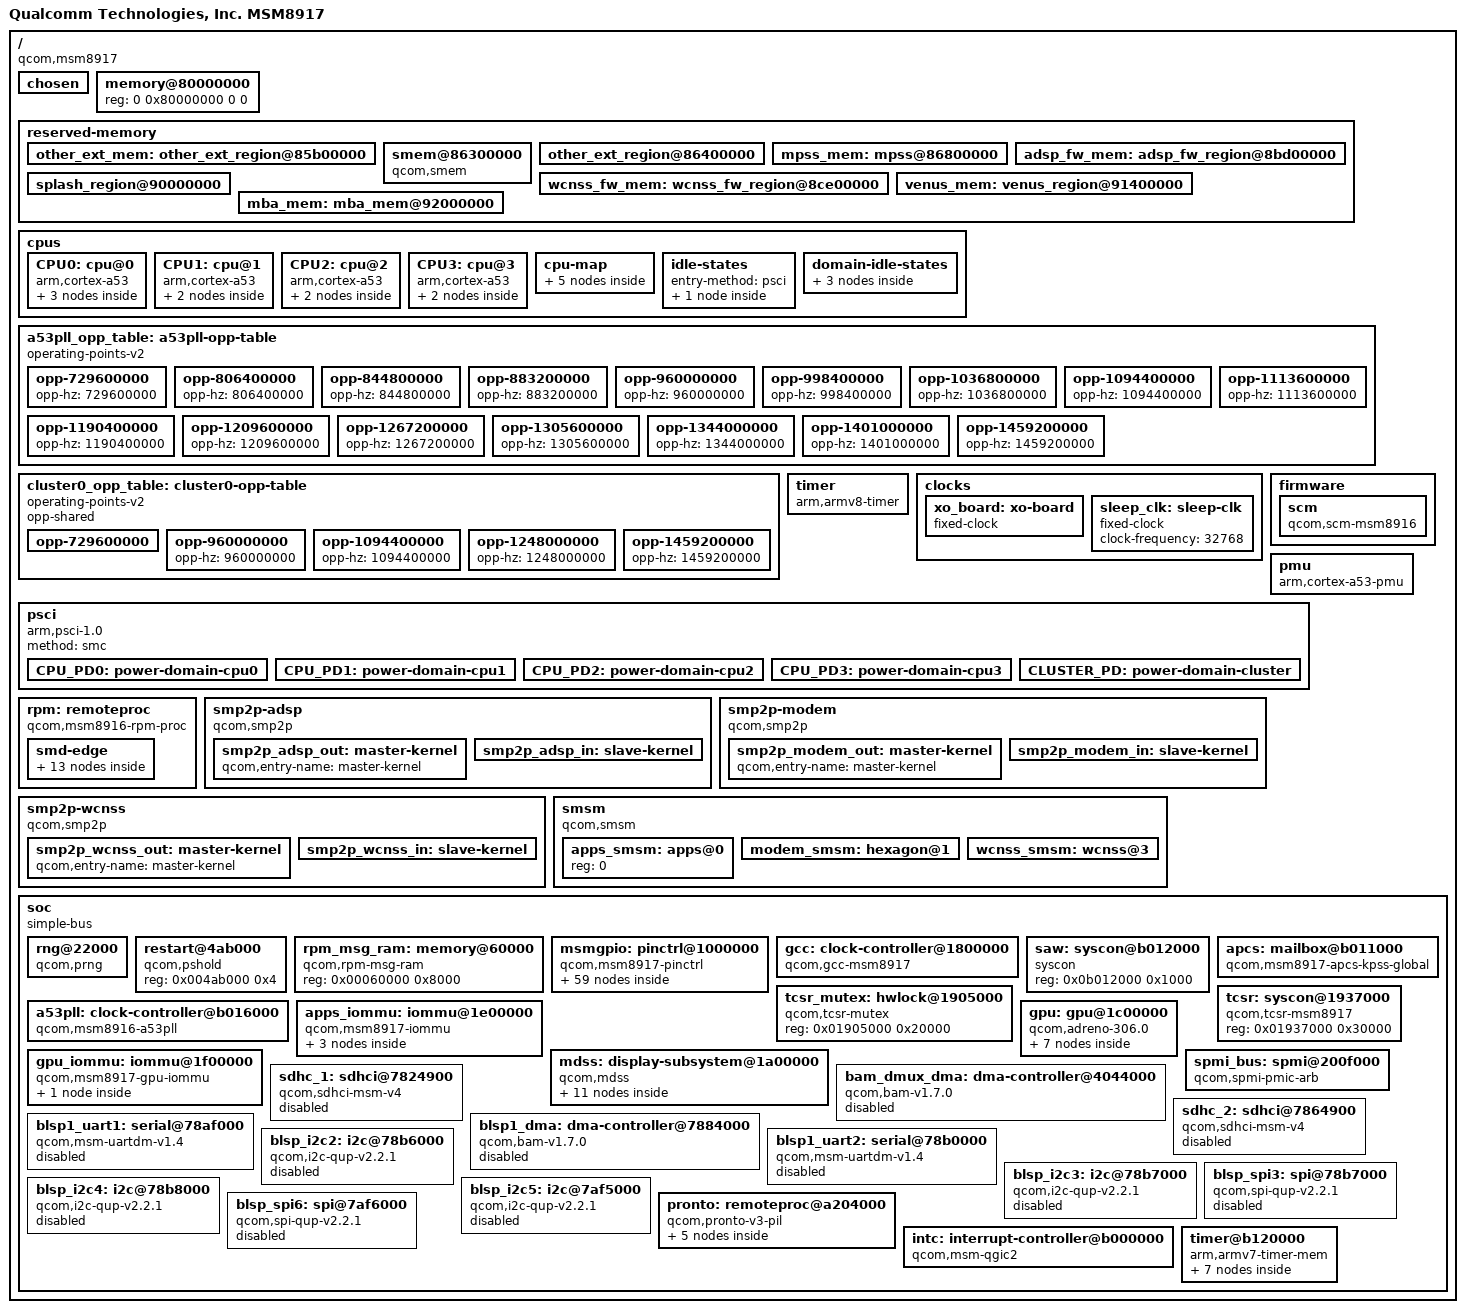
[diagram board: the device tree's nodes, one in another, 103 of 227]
// SPDX-License-Identifier: GPL-2.0-only

#include <dt-bindings/clock/qcom,gcc-msm8917.h>
#include <dt-bindings/clock/qcom,rpmcc.h>
#include <dt-bindings/interrupt-controller/arm-gic.h>
#include <dt-bindings/power/qcom-rpmpd.h>

/ {
	model = "Qualcomm Technologies, Inc. MSM8917";
	compatible = "qcom,msm8917";
	qcom,msm-id = <303 0x0>, <308 0x0>, <309 0x0>;
	interrupt-parent = <&intc>;

	#address-cells = <2>;
	#size-cells = <2>;

	chosen { };

	memory@80000000 {
		device_type = "memory";
		/* We expect the bootloader to fill in the reg */
		reg = <0 0x80000000 0 0>;
	};

	reserved-memory {
		#address-cells = <2>;
		#size-cells = <2>;
		ranges;

		other_ext_mem: other_ext_region@85b00000 {
			reg = <0x0 0x85b00000 0x0 0xd00000>;
			no-map;
		};

		smem@86300000 {
			compatible = "qcom,smem";
			reg = <0x0 0x86300000 0x0 0x100000>;
			no-map;

			hwlocks = <&tcsr_mutex 3>;
			qcom,rpm-msg-ram = <&rpm_msg_ram>;
		};

		other_ext_region@86400000 {
			reg = <0x0 0x86400000 0x0 0x400000>;
			no-map;
		};

		mpss_mem: mpss@86800000 {
			reg = <0x0 0x86800000 0x0 0x5500000>;
			no-map;
		};

		adsp_fw_mem: adsp_fw_region@8bd00000 {
			reg = <0x0 0x8bd00000 0x0 0x1100000>;
			no-map;
		};

		wcnss_fw_mem: wcnss_fw_region@8ce00000 {
			reg = <0x0 0x8ce00000 0x0 0x700000>;
			no-map;
		};

		splash_region@90000000 {
			reg = <0x0 0x90000000 0x0 0x1400000>;
			no-map;
		};

		venus_mem: venus_region@91400000 {
			reg = <0x0 0x91400000 0x0 0x700000>;
			no-map;
		};

		mba_mem: mba_mem@92000000 {
			reg = <0x0 0x92000000 0x0 0x100000>;
			no-map;
		};
	};

	cpus {
		#address-cells = <1>;
		#size-cells = <0>;
		CPU0: cpu@0 {
			device_type = "cpu";
			compatible = "arm,cortex-a53";
			capacity-dmips-mhz = <1024>;
			reg = <0x100>;
			next-level-cache = <&L2_0>;
			enable-method = "psci";
			clocks = <&apcs>;
			#cooling-cells = <2>;
			operating-points-v2 = <&cluster0_opp_table>;
			power-domains = <&CPU_PD0>;
			power-domain-names = "psci";
			l1-icache { compatible = "cache"; };
			l1-dcache { compatible = "cache"; };
			L2_0: l2-cache {
				compatible = "cache";
				cache-level = <2>;
				cache-unified;
			};
		};

		CPU1: cpu@1 {
			device_type = "cpu";
			compatible = "arm,cortex-a53";
			capacity-dmips-mhz = <1024>;
			reg = <0x101>;
			next-level-cache = <&L2_0>;
			enable-method = "psci";
			clocks = <&apcs>;
			#cooling-cells = <2>;
			operating-points-v2 = <&cluster0_opp_table>;
			power-domains = <&CPU_PD0>;
			power-domain-names = "psci";
			l1-icache { compatible = "cache"; };
			l1-dcache { compatible = "cache"; };
		};

		CPU2: cpu@2 {
			device_type = "cpu";
			compatible = "arm,cortex-a53";
			capacity-dmips-mhz = <1024>;
			reg = <0x102>;
			next-level-cache = <&L2_0>;
			enable-method = "psci";
			clocks = <&apcs>;
			#cooling-cells = <2>;
			operating-points-v2 = <&cluster0_opp_table>;
			power-domains = <&CPU_PD0>;
			power-domain-names = "psci";
			l1-icache { compatible = "cache"; };
			l1-dcache { compatible = "cache"; };
		};

		CPU3: cpu@3 {
			device_type = "cpu";
			compatible = "arm,cortex-a53";
			capacity-dmips-mhz = <1024>;
			reg = <0x103>;
			next-level-cache = <&L2_0>;
			enable-method = "psci";
			clocks = <&apcs>;
			#cooling-cells = <2>;
			operating-points-v2 = <&cluster0_opp_table>;
			power-domains = <&CPU_PD0>;
			power-domain-names = "psci";
			l1-icache { compatible = "cache"; };
			l1-dcache { compatible = "cache"; };
		};

		cpu-map {
			cluster0 {
				core0 {
					cpu = <&CPU0>;
				};
				core1 {
					cpu = <&CPU1>;
				};
				core2 {
					cpu = <&CPU2>;
				};
				core3 {
					cpu = <&CPU3>;
				};
			};
		};

		idle-states {
			entry-method = "psci";

			CPU_SLEEP_0: cpu-sleep-0 {
				compatible = "arm,idle-state";
				idle-state-name = "standalone-power-collapse";
				arm,psci-suspend-param = <0x40000003>;
				entry-latency-us = <125>;
				exit-latency-us = <180>;
				min-residency-us = <595>;
				local-timer-stop;
			};
		};

		domain-idle-states {
			CLUSTER_PWRDN: cluster-gdhs {
				compatible = "domain-idle-state";
				arm,psci-suspend-param = <0x41000043>;
				entry-latency-us = <240>;
				exit-latency-us = <280>;
				min-residency-us = <806>;
			};

			CLUSTER_RET: cluster-retention {
				compatible = "domain-idle-state";
				arm,psci-suspend-param = <0x41000023>;
				entry-latency-us = <700>;
				exit-latency-us = <650>;
				min-residency-us = <1972>;
			};

			CLUSTER_PC: cluster-power-collapse {
				compatible = "domain-idle-state";
				arm,psci-suspend-param = <0x41000053>;
				entry-latency-us = <700>;
				exit-latency-us = <1000>;
				min-residency-us = <6500>;
			};
		};
	};

	a53pll_opp_table: a53pll-opp-table {
		compatible = "operating-points-v2";
		opp-729600000 { opp-hz = /bits/ 64 <729600000>; };
		opp-806400000 { opp-hz = /bits/ 64 <806400000>; };
		opp-844800000 { opp-hz = /bits/ 64 <844800000>; };
		opp-883200000 { opp-hz = /bits/ 64 <883200000>; };
		opp-960000000 { opp-hz = /bits/ 64 <960000000>; };
		opp-998400000 { opp-hz = /bits/ 64 <998400000>; };
		opp-1036800000 { opp-hz = /bits/ 64 <1036800000>; };
		opp-1094400000 { opp-hz = /bits/ 64 <1094400000>; };
		opp-1113600000 { opp-hz = /bits/ 64 <1113600000>; };
		opp-1190400000 { opp-hz = /bits/ 64 <1190400000>; };
		opp-1209600000 { opp-hz = /bits/ 64 <1209600000>; };
		opp-1267200000 { opp-hz = /bits/ 64 <1267200000>; };
		opp-1305600000 { opp-hz = /bits/ 64 <1305600000>; };
		opp-1344000000 { opp-hz = /bits/ 64 <1344000000>; };
		opp-1401000000 { opp-hz = /bits/ 64 <1401000000>; };
		opp-1459200000 { opp-hz = /bits/ 64 <1459200000>; };
	};

	cluster0_opp_table: cluster0-opp-table {
		compatible = "operating-points-v2";
		opp-shared;
		
		opp-729600000 {
			opp-hz = /bits/ 64 <729600000>;
			opp-suspend;
		};
		opp-960000000 {
			opp-hz = /bits/ 64 <960000000>;
		};
		opp-1094400000 {
			opp-hz = /bits/ 64 <1094400000>;
		};
		opp-1248000000 {
			opp-hz = /bits/ 64 <1248000000>;
		};
		opp-1459200000 {
			opp-hz = /bits/ 64 <1459200000>;
		};
	};

	timer {
		compatible = "arm,armv8-timer";
		interrupts = <GIC_PPI 2 (GIC_CPU_MASK_SIMPLE(4) | IRQ_TYPE_LEVEL_LOW)>,
			     <GIC_PPI 3 (GIC_CPU_MASK_SIMPLE(4) | IRQ_TYPE_LEVEL_LOW)>,
			     <GIC_PPI 4 (GIC_CPU_MASK_SIMPLE(4) | IRQ_TYPE_LEVEL_LOW)>,
			     <GIC_PPI 1 (GIC_CPU_MASK_SIMPLE(4) | IRQ_TYPE_LEVEL_LOW)>;
		clock-frequency = <19200000>;
	};

	clocks {
		xo_board: xo-board {
			compatible = "fixed-clock";
			#clock-cells = <0>;
			clock-frequency = <19200000>;
			clock-output-names = "xo";
		};

		sleep_clk: sleep-clk {
			compatible = "fixed-clock";
			#clock-cells = <0>;
			clock-frequency = <32768>;
		};
	};

	firmware {
		scm: scm {
			compatible = "qcom,scm-msm8916", "qcom,scm";
			clocks = <&gcc GCC_CRYPTO_CLK>,
				 <&gcc GCC_CRYPTO_AXI_CLK>,
				 <&gcc GCC_CRYPTO_AHB_CLK>;
			clock-names = "core", "bus", "iface";
			#reset-cells = <1>;
		};
	};

	pmu {
		compatible = "arm,cortex-a53-pmu";
		interrupts = <GIC_PPI 7 (GIC_CPU_MASK_SIMPLE(4) | IRQ_TYPE_LEVEL_HIGH)>;
	};

	psci {
		compatible = "arm,psci-1.0";
		method = "smc";

		CPU_PD0: power-domain-cpu0 {
			#power-domain-cells = <0>;
			power-domains = <&CLUSTER_PD>;
			domain-idle-states = <&CPU_SLEEP_0>;
		};

		CPU_PD1: power-domain-cpu1 {
			#power-domain-cells = <0>;
			power-domains = <&CLUSTER_PD>;
			domain-idle-states = <&CPU_SLEEP_0>;
		};

		CPU_PD2: power-domain-cpu2 {
			#power-domain-cells = <0>;
			power-domains = <&CLUSTER_PD>;
			domain-idle-states = <&CPU_SLEEP_0>;
		};

		CPU_PD3: power-domain-cpu3 {
			#power-domain-cells = <0>;
			power-domains = <&CLUSTER_PD>;
			domain-idle-states = <&CPU_SLEEP_0>;
		};

		CLUSTER_PD: power-domain-cluster {
			#power-domain-cells = <0>;
			domain-idle-states = <&CLUSTER_PWRDN>, <&CLUSTER_RET>, <&CLUSTER_PC>;
		};
	};

	rpm: remoteproc {
		compatible = "qcom,msm8916-rpm-proc", "qcom,rpm-proc";

		smd-edge {
			interrupts = <GIC_SPI 168 IRQ_TYPE_EDGE_RISING>;
			qcom,ipc = <&apcs 8 0>;
			qcom,smd-edge = <15>;

			rpm_requests: rpm-requests {
				compatible = "qcom,rpm-msm8916";
				qcom,smd-channels = "rpm_requests";

				rpmcc: clock-controller {
					compatible = "qcom,rpmcc-msm8917", "qcom,rpmcc";
					#clock-cells = <1>;
					clocks = <&xo_board>;
					clock-names = "xo";
				};

				rpmpd: power-controller {
					compatible = "qcom,msm8937-rpmpd";
					#power-domain-cells = <1>;
					operating-points-v2 = <&rpmpd_opp_table>;

					rpmpd_opp_table: opp-table {
						compatible = "operating-points-v2";

						rpmpd_opp_ret: opp1 {
							opp-level = <RPM_SMD_LEVEL_RETENTION>;
						};

						rpmpd_opp_ret_plus: opp2 {
							opp-level = <RPM_SMD_LEVEL_RETENTION_PLUS>;
						};

						rpmpd_opp_min_svs: opp3 {
							opp-level = <RPM_SMD_LEVEL_MIN_SVS>;
						};

						rpmpd_opp_low_svs: opp4 {
							opp-level = <RPM_SMD_LEVEL_LOW_SVS>;
						};

						rpmpd_opp_svs: opp5 {
							opp-level = <RPM_SMD_LEVEL_SVS>;
						};

						rpmpd_opp_svs_plus: opp6 {
							opp-level = <RPM_SMD_LEVEL_SVS_PLUS>;
						};

						rpmpd_opp_nom: opp7 {
							opp-level = <RPM_SMD_LEVEL_NOM>;
						};

						rpmpd_opp_nom_plus: opp8 {
							opp-level = <RPM_SMD_LEVEL_NOM_PLUS>;
						};

						rpmpd_opp_turbo: opp9 {
							opp-level = <RPM_SMD_LEVEL_TURBO>;
						};
					};	
				};
			};
		};
	};

	smp2p-adsp {
		compatible = "qcom,smp2p";
		qcom,smem = <443>, <429>;
		interrupts = <GIC_SPI 291 IRQ_TYPE_EDGE_RISING>;
		mboxes = <&apcs 10>;
		qcom,local-pid = <0>;
		qcom,remote-pid = <2>;

		smp2p_adsp_out: master-kernel {
			qcom,entry-name = "master-kernel";
			#qcom,smem-state-cells = <1>;
		};

		smp2p_adsp_in: slave-kernel {
			qcom,entry-name = "slave-kernel";
			interrupt-controller;
			#interrupt-cells = <2>;
		};
	};
	
	smp2p-modem {
		compatible = "qcom,smp2p";
		qcom,smem = <435>, <428>;
		interrupts = <GIC_SPI 27 IRQ_TYPE_EDGE_RISING>;
		qcom,ipc = <&apcs 8 14>;
		qcom,local-pid = <0>;
		qcom,remote-pid = <1>;

		smp2p_modem_out: master-kernel {
			qcom,entry-name = "master-kernel";
			#qcom,smem-state-cells = <1>;
		};

		smp2p_modem_in: slave-kernel {
			qcom,entry-name = "slave-kernel";
			interrupt-controller;
			#interrupt-cells = <2>;
		};
	};

	smp2p-wcnss {
		compatible = "qcom,smp2p";
		qcom,smem = <451>, <431>;
		interrupts = <GIC_SPI 143 IRQ_TYPE_EDGE_RISING>;
		qcom,ipc = <&apcs 8 18>;
		qcom,local-pid = <0>;
		qcom,remote-pid = <4>;

		smp2p_wcnss_out: master-kernel {
			qcom,entry-name = "master-kernel";
			#qcom,smem-state-cells = <1>;
		};

		smp2p_wcnss_in: slave-kernel {
			qcom,entry-name = "slave-kernel";

			interrupt-controller;
			#interrupt-cells = <2>;
		};
	};

	smsm {
		compatible = "qcom,smsm";

		#address-cells = <1>;
		#size-cells = <0>;

		qcom,ipc-1 = <&apcs 8 13>;
		qcom,ipc-3 = <&apcs 8 19>;

		apps_smsm: apps@0 {
			reg = <0>;
			#qcom,smem-state-cells = <1>;
		};

		modem_smsm: hexagon@1 {
			reg = <1>;
			interrupts = <GIC_SPI 26 IRQ_TYPE_EDGE_RISING>;

			interrupt-controller;
			#interrupt-cells = <2>;
		};

		wcnss_smsm: wcnss@3 {
			reg = <3>;
			interrupts = <GIC_SPI 144 IRQ_TYPE_EDGE_RISING>;

			interrupt-controller;
			#interrupt-cells = <2>;
		};
	};

	soc: soc {
		#address-cells = <1>;
		#size-cells = <1>;
		ranges = <0 0 0 0xffffffff>;
		compatible = "simple-bus";

		rng@22000 {
			compatible = "qcom,prng";
			reg = <0x00022000 0x200>;
			clocks = <&gcc GCC_PRNG_AHB_CLK>;
			clock-names = "core";
		};

		restart@4ab000 {
			compatible = "qcom,pshold";
			reg = <0x004ab000 0x4>;
		};

		rpm_msg_ram: memory@60000 {
			compatible = "qcom,rpm-msg-ram";
			reg = <0x00060000 0x8000>;
		};

		msmgpio: pinctrl@1000000 {
			compatible = "qcom,msm8917-pinctrl";
			reg = <0x01000000 0x300000>;
			interrupts = <GIC_SPI 208 IRQ_TYPE_LEVEL_HIGH>;
			gpio-controller;
			gpio-ranges = <&msmgpio 0 0 134>;
			gpio-reserved-ranges = <0 4>, <20 4>;
			#gpio-cells = <2>;
			interrupt-controller;
			#interrupt-cells = <2>;

			/* BLSP PINs */
			uart_console_active: uart-console-active-pins {
				pins = "gpio4", "gpio5";
				function = "blsp_uart2";
				drive-strength = <2>;
				bias-disable;
			};

			uart_console_sleep: uart-console-sleep-pins {
				pins = "gpio4", "gpio5";
				function = "blsp_uart2";
				drive-strength = <2>;
				bias-pull-down;
			};

			blsp1_uart1_active: blsp1_uart1_active {
				pins = "gpio0", "gpio1",
					"gpio2", "gpio3";
				function = "blsp_uart1";
				drive-strength = <2>;
				bias-disable;
			};

			blsp1_uart1_sleep: blsp1_uart1_sleep {
				pins = "gpio0", "gpio1",
					"gpio2", "gpio3";
				function = "gpio";
				drive-strength = <2>;
				bias-disable;
			};

			blsp2_uart1_active: blsp2_uart1_active {
				pins = "gpio16", "gpio17", "gpio18", "gpio19";
				function = "blsp_uart5";
				drive-strength = <2>;
				bias-disable;
			};

			blsp2_uart1_sleep: blsp2_uart1_sleep {
				pins = "gpio16", "gpio17", "gpio18", "gpio19";
				function = "gpio";
				drive-strength = <2>;
				bias-disable;
			};

			blsp2_uart2_active: blsp2_uart2_active {
				pins = "gpio20", "gpio21", "gpio22", "gpio23";
				function = "blsp_uart6";
				drive-strength = <2>;
				bias-disable;
			};

			blsp2_uart2_sleep: blsp2_uart2_sleep {
				pins = "gpio20", "gpio21", "gpio22", "gpio23";
				function = "gpio";
				drive-strength = <2>;
				bias-disable;
			};

			i2c_2_default: i2c-2-default-pins {
				pins = "gpio6", "gpio7";
				function = "blsp_i2c2";
				drive-strength = <2>;
				bias-disable;
			};

			i2c_2_sleep: i2c-2-sleep-pins {
				pins = "gpio6", "gpio7";
				function = "gpio";
				drive-strength = <2>;
				bias-disable;
			};

			i2c_3_default: i2c-3-default-pins {
				pins = "gpio10", "gpio11";
				function = "blsp_i2c3";
				drive-strength = <2>;
				bias-disable;
			};

			i2c_3_sleep: i2c-3-sleep-pins {
				pins = "gpio10", "gpio11";
				function = "gpio";
				drive-strength = <2>;
				bias-disable;
			};

			i2c_4_default: i2c-4-default-pins {
				pins = "gpio14", "gpio15";
				function = "blsp_i2c4";
				drive-strength = <2>;
				bias-disable;
			};

			i2c_4_sleep: i2c-4-sleep-pins {
				pins = "gpio14", "gpio15";
				function = "gpio";
				drive-strength = <2>;
				bias-disable;
			};

			i2c_5_default: i2c-5-default-pins {
				pins = "gpio18", "gpio19";
				function = "blsp_i2c5";
				drive-strength = <2>;
				bias-disable;
			};

			i2c_5_sleep: i2c-5-sleep-pins {
				pins = "gpio18", "gpio19";
				function = "gpio";
				drive-strength = <2>;
				bias-disable;
			};

			i2c_6_default: i2c-6-default-pins {
				pins = "gpio22", "gpio23";
				function = "blsp_i2c6";
				drive-strength = <2>;
				bias-disable;
			};

			i2c_6_sleep: i2c-6-sleep-pins {
				pins = "gpio22", "gpio23";
				function = "gpio";
				drive-strength = <2>;
				bias-disable;
			};

			spi3_default: spi3_default {
				pins = "gpio8", "gpio9", "gpio11";
				function = "blsp_spi3";
				drive-strength = <12>;
				bias-disable;
			};

			spi3_sleep: spi3_sleep {
				pins = "gpio8", "gpio9", "gpio11";
				function = "gpio";
				drive-strength = <2>;
				bias-pull-down;
			};

			spi6_default: spi6_default {
				pins = "gpio20", "gpio21", "gpio23";
				function = "blsp_spi6";
				drive-strength = <16>;
				bias-disable;
			};

			spi6_sleep: spi6_sleep {
				pins = "gpio20", "gpio21", "gpio23";
				function = "gpio";
				drive-strength = <2>;
				bias-pull-down;
			};

			/* SDHCI PINs */
			sdc1_clk_on: sdc1-clk-on-pins {
				pins = "sdc1_clk";
				bias-disable;
				drive-strength = <16>;
			};

			sdc1_clk_off: sdc1-clk-off-pins {
				pins = "sdc1_clk";
				bias-disable;
				drive-strength = <2>;
			};

			sdc1_cmd_on: sdc1-cmd-on-pins {
				pins = "sdc1_cmd";
				bias-disable;
				drive-strength = <10>;
			};

			sdc1_cmd_off: sdc1-cmd-off-pins {
				pins = "sdc1_cmd";
				num-grp-pins = <1>;
				bias-disable;
				drive-strength = <2>;
			};

			sdc1_data_on: sdc1-data-on-pins {
				pins = "sdc1_data";
				bias-pull-up;
				drive-strength = <10>;
			};

			sdc1_data_off: sdc1-data-off-pins {
				pins = "sdc1_data";
				bias-pull-up;
				drive-strength = <2>;
			};

			sdc1_rclk_on: sdc1-rclk-on-pins {
				pins = "sdc1_rclk";
				bias-pull-down;
			};

			sdc1_rclk_off: sdc1-rclk-off-pins {
				pins = "sdc1_rclk";
				bias-pull-down;
			};

			sdc2_clk_on: sdc2-clk-on-pins {
				pins = "sdc2_clk";
				drive-strength = <16>;
				bias-disable;
			};

			sdc2_clk_off: sdc2-clk-off-pins {
				pins = "sdc2_clk";
				bias-disable;
				drive-strength = <2>;
			};

			sdc2_cmd_on: sdc2-cmd-on-pins {
				pins = "sdc2_cmd";
				bias-pull-up;
				drive-strength = <10>;
			};

			sdc2_cmd_off: sdc2-cmd-off-pins {
				pins = "sdc2_cmd";
				bias-pull-up;
				drive-strength = <2>;
			};

			sdc2_data_on: sdc2-data-on-pins {
				pins = "sdc2_data";
				bias-pull-up;
				drive-strength = <10>;
			};

			sdc2_data_off: sdc2-data-off-pins {
				pins = "sdc2_data";
				bias-pull-up;
				drive-strength = <2>;
			};

			sdc2_cd_on: cd-on-pins {
				pins = "gpio67";
				function = "gpio";
				drive-strength = <2>;
				bias-pull-up;
			};

			sdc2_cd_off: cd-off-pins {
				pins = "gpio67";
				function = "gpio";
				drive-strength = <2>;
				bias-disable;
			};

			/* BUS PINs */
			wcnss_default: wcnss-default-pins {
				wcss_wlan2 {
					pins = "gpio76";
					function = "wcss_wlan2";
				};

				wcss_wlan1 {
					pins = "gpio77";
					function = "wcss_wlan1";
				};

				wcss_wlan0 {
					pins = "gpio78";
					function = "wcss_wlan0";
				};

				wcss_wlan {
					pins = "gpio79", "gpio80";
					function = "wcss_wlan";
				};

				pinconf {
					pins = "gpio76", "gpio77", "gpio78",
					       "gpio79", "gpio80";
					drive-strength = <6>;
					bias-pull-up;
				};
			};

			wcnss_sleep: wcnss-sleep-pins {
				wcss_wlan2 {
					pins = "gpio76";
					function = "wcss_wlan2";
				};

				wcss_wlan1 {
					pins = "gpio77";
					function = "wcss_wlan1";
				};

				wcss_wlan0 {
					pins = "gpio78";
					function = "wcss_wlan0";
				};

				wcss_wlan {
					pins = "gpio79", "gpio80";
					function = "wcss_wlan";
				};

				pinconf {
					pins = "gpio76", "gpio77",
						"gpio78", "gpio79",
						"gpio80";
					drive-strength = <2>;
					bias-pull-down;
				};
			};

			cdc_pdm_lines_2_act: pdm-lines-2-on-pins {
					pins = "gpio70", "gpio71", "gpio72";
					function = "cdc_pdm0";
					drive-strength = <8>;
			};

			cdc_pdm_lines_2_sus: pdm-lines-2-off-pins {
					pins = "gpio70", "gpio71", "gpio72";
					function = "cdc_pdm0";
					drive-strength = <2>;
					bias-disable;
			};

			cdc_pdm_lines_act: pdm-lines-on-pins {
					pins = "gpio69", "gpio73", "gpio74";
					function = "cdc_pdm0";
					drive-strength = <8>;
			};

			cdc_pdm_lines_sus: pdm-lines-off-pins {
					pins = "gpio69", "gpio73", "gpio74";
					function = "cdc_pdm0";
					drive-strength = <2>;
					bias-disable;
			};

			/* MDP PINs */
			mdss_dsi_active: mdss_dsi_active {
				pins = "gpio60", "gpio98", "gpio99";
				function = "gpio";
				drive-strength = <8>;
				bias-disable = <0>;
				output-high;
			};

			mdss_dsi_suspend: mdss_dsi_suspend {
				pins = "gpio60", "gpio98", "gpio99";
				function = "gpio";
				drive-strength = <2>;
				bias-pull-down;
				input-enable;
			};

			mdss_te_active: mdss_te_active {
				pins = "gpio24";
				function = "mdp_vsync";
				drive-strength = <2>;
				bias-pull-down;
			};

			mdss_te_suspend: mdss_te_suspend {
				pins = "gpio24";
				function = "mdp_vsync";
				drive-strength = <2>;
				bias-pull-down;
			};

			/* MISC PINs */
			gpio_key_default: gpio-key-default-pins {
				pins = "gpio91", "gpio127", "gpio128";
				function = "gpio";
				drive-strength = <2>;
				bias-pull-up;
			};
		};

		gcc: clock-controller@1800000 {
			compatible = "qcom,gcc-msm8917", "syscon";
			#clock-cells = <1>;
			#reset-cells = <1>;
			#power-domain-cells = <1>;
			reg = <0x01800000 0x80000>;
			clocks = <&xo_board>,
				 <&sleep_clk>,
				 <&dsi_phy0 1>,
				 <&dsi_phy0 0>;
			clock-names = "xo",
				      "sleep_clk",
				      "dsi0pll",
				      "dsi0pllbyte";
		};

		saw: syscon@b012000 {
			compatible = "syscon";
			reg = <0x0b012000 0x1000>;
		};

		a53pll: clock-controller@b016000 {
			compatible = "qcom,msm8916-a53pll";
			reg = <0x0b016000 0x34>;
			#clock-cells = <0>;
			clocks = <&xo_board>;
			clock-names = "xo";
			operating-points-v2 = <&a53pll_opp_table>;
		};

		apcs: mailbox@b011000 {
			compatible = "qcom,msm8917-apcs-kpss-global", "syscon";
			reg = <0x0b011000 0x1000>;
			#mbox-cells = <1>;
			clocks = <&a53pll>, <&gcc GPLL0_EARLY>;
			clock-names = "pll", "aux";
			#clock-cells = <0>;
		};

		tcsr_mutex: hwlock@1905000 {
			compatible = "qcom,tcsr-mutex";
			reg = <0x01905000 0x20000>;
			#hwlock-cells = <1>;
		};

		tcsr: syscon@1937000 {
			compatible = "qcom,tcsr-msm8917", "syscon";
			reg = <0x01937000 0x30000>;
		};

		apps_iommu: iommu@1e00000 {
			#address-cells = <1>;
			#size-cells = <1>;
			#iommu-cells = <1>;
			compatible = "qcom,msm8917-iommu", "qcom,msm-iommu-v1";
			ranges = <0 0x01e20000 0x20000>;

			clocks = <&gcc GCC_SMMU_CFG_CLK>,
				 <&gcc GCC_APSS_TCU_CLK>;
			clock-names = "iface", "bus";

			qcom,iommu-secure-id = <17>;

			/* VFE */
			iommu-ctx@14000 {
				compatible = "qcom,msm-iommu-v1-ns";
				reg = <0x00014000 0x1000>;
				interrupts = <GIC_SPI 111 IRQ_TYPE_LEVEL_HIGH>;
			};

			/* MDP_0 */
			iommu-ctx@15000 {
				compatible = "qcom,msm-iommu-v1-ns";
				reg = <0x00015000 0x1000>;
				interrupts = <GIC_SPI 112 IRQ_TYPE_LEVEL_HIGH>;
			};

			/* VENUS_NS */
			iommu-ctx@16000 {
				compatible = "qcom,msm-iommu-v1-ns";
				reg = <0x00016000 0x1000>;
				interrupts = <GIC_SPI 113 IRQ_TYPE_LEVEL_HIGH>;
			};
		};

		gpu_iommu: iommu@1f00000 {
			#address-cells = <1>;
			#size-cells = <1>;
			#iommu-cells = <1>;

			compatible = "qcom,msm8917-gpu-iommu", "qcom,msm-iommu-v1";

			ranges = <0 0x01f08000 0x10000>;
			clocks = <&gcc GCC_SMMU_CFG_CLK>,
				 <&gcc GCC_GFX_TCU_CLK>;
			clock-names = "iface", "bus";
			qcom,iommu-secure-id = <18>;

			/* GFX3D_USER */
			iommu-ctx@0 {
				compatible = "qcom,msm-iommu-v2-ns";
				reg = <0x0000 0x1000>;
				interrupts = <GIC_SPI 240 IRQ_TYPE_LEVEL_HIGH>;
			};
		};

		mdss: display-subsystem@1a00000 {
			compatible = "qcom,mdss";
			reg = <0x01a00000 0x1000>,
			      <0x01ab0000 0x1040>;
			reg-names = "mdss_phys", "vbif_phys";

			power-domains = <&gcc MDSS_GDSC>;

			clocks = <&gcc GCC_MDSS_AHB_CLK>,
				 <&gcc GCC_MDSS_AXI_CLK>,
				 <&gcc GCC_MDSS_VSYNC_CLK>,
				 <&gcc GCC_MDSS_MDP_CLK>;
			clock-names = "iface",
				      "bus",
				      "vsync",
				      "core";

			interrupts = <GIC_SPI 72 IRQ_TYPE_LEVEL_HIGH>;

			interrupt-controller;
			#interrupt-cells = <1>;

			#address-cells = <1>;
			#size-cells = <1>;
			ranges;

			mdp: display-controller@1a01000 {
				compatible = "qcom,mdp5";
				reg = <0x01a01000 0x89000>;
				reg-names = "mdp_phys";

				interrupt-parent = <&mdss>;
				interrupts = <0>;

				power-domains = <&gcc MDSS_GDSC>;

				clocks = <&gcc GCC_MDSS_AHB_CLK>,
					 <&gcc GCC_MDSS_AXI_CLK>,
					 <&gcc GCC_MDSS_MDP_CLK>,
					 <&gcc GCC_MDSS_VSYNC_CLK>;
				clock-names = "iface",
					      "bus",
					      "core",
					      "vsync";

				iommus = <&apps_iommu 0x15>;

				ports {
					#address-cells = <1>;
					#size-cells = <0>;

					port@0 {
						reg = <0>;
						mdp5_intf1_out: endpoint {
							remote-endpoint = <&dsi0_in>;
						};
					};
				};
			};

			dsi0: dsi@1a94000 {
				compatible = "qcom,mdss-dsi-ctrl";
				reg = <0x01a94000 0x300>;
				reg-names = "dsi_ctrl";

				interrupt-parent = <&mdss>;
				interrupts = <4>;

				assigned-clocks = <&gcc BYTE0_CLK_SRC>,
						  <&gcc PCLK0_CLK_SRC>;
				assigned-clock-parents = <&dsi_phy0 0>,
							 <&dsi_phy0 1>;

				clocks = <&gcc GCC_MDSS_MDP_CLK>,
					 <&gcc GCC_MDSS_AHB_CLK>,
					 <&gcc GCC_MDSS_AXI_CLK>,
					 <&gcc GCC_MDSS_BYTE0_CLK>,
					 <&gcc GCC_MDSS_PCLK0_CLK>,
					 <&gcc GCC_MDSS_ESC0_CLK>;
				clock-names = "mdp_core",
					      "iface",
					      "bus",
					      "byte",
					      "pixel",
					      "core";
				phys = <&dsi_phy0>;
				phy-names = "dsi-phy";

				#address-cells = <1>;
				#size-cells = <0>;

				ports {
					#address-cells = <1>;
					#size-cells = <0>;

					port@0 {
						reg = <0>;
						dsi0_in: endpoint {
							remote-endpoint = <&mdp5_intf1_out>;
						};
					};

					port@1 {
						reg = <1>;
						dsi0_out: endpoint {
						};
					};
				};
			};

			dsi_phy0: phy@1a94400 {
				compatible = "qcom,dsi-phy-28nm-8917";
				reg = <0x01a94a00 0xd4>,
				      <0x01a94400 0x280>,
				      <0x01a94b80 0x30>;
				reg-names = "dsi_pll",
					    "dsi_phy",
					    "dsi_phy_regulator";

				#clock-cells = <1>;
				#phy-cells = <0>;

				clocks = <&gcc GCC_MDSS_AHB_CLK>,
					 <&xo_board>;
				clock-names = "iface", "ref";
			};
		};

		gpu: gpu@1c00000 {
			compatible = "qcom,adreno-306.0", "qcom,adreno";
			reg = <0x01c00000 0x20000>;
			reg-names = "kgsl_3d0_reg_memory";
			interrupts = <GIC_SPI 33 IRQ_TYPE_LEVEL_HIGH>;
			interrupt-names = "kgsl_3d0_irq";
			clock-names = "core", 
						  "iface", 
						  "mem_iface",
						  "alt_mem_iface", 
						  "gtcu_iface",
						  "gtcu", 
						  "gtbu",
						  "gfx3d";
			clocks = <&gcc GCC_OXILI_GFX3D_CLK>,
				 <&gcc GCC_OXILI_AHB_CLK>,
				 <&gcc GCC_BIMC_GFX_CLK>,
				 <&gcc GCC_BIMC_GPU_CLK>,
				 <&gcc GCC_GTCU_AHB_CLK>,
				 <&gcc GCC_GFX_TCU_CLK>,
				 <&gcc GCC_GFX_TBU_CLK>,
				 <&gcc GFX3D_CLK_SRC>;
			power-domains = <&gcc OXILI_GX_GDSC>;
			operating-points-v2 = <&gpu_opp_table>;
			#cooling-cells = <2>;
			iommus = <&gpu_iommu 0>;

			gpu_opp_table: opp-table {
				compatible  ="operating-points-v2";
				opp-598000000 {
					opp-hz = /bits/ 64 <598000000>;
				};
				opp-523200000 {
					opp-hz = /bits/ 64 <523200000>;
				};
				opp-484800000 {
					opp-hz = /bits/ 64 <484800000>;
				};
				opp-400000000 {
					opp-hz = /bits/ 64 <400000000>;
				};
				opp-270000000 {
					opp-hz = /bits/ 64 <270000000>;
				};
				opp-19200000 {
					opp-hz = /bits/ 64 <19200000>;
				};
			};
		};

		spmi_bus: spmi@200f000 {
			compatible = "qcom,spmi-pmic-arb";
			reg = <0x0200f000 0x001000>,
			      <0x02400000 0x800000>,
			      <0x02c00000 0x800000>,
			      <0x03800000 0x200000>,
			      <0x0200a000 0x002100>;
			reg-names = "core", "chnls", "obsrvr", "intr", "cnfg";
			interrupt-names = "periph_irq";
			interrupts = <GIC_SPI 190 IRQ_TYPE_LEVEL_HIGH>;
			qcom,ee = <0>;
			qcom,channel = <0>;
			#address-cells = <2>;
			#size-cells = <0>;
			interrupt-controller;
			#interrupt-cells = <4>;
		};

		bam_dmux_dma: dma-controller@4044000 {
			compatible = "qcom,bam-v1.7.0";
			reg = <0x04044000 0x19000>;
			interrupts = <GIC_SPI 29 IRQ_TYPE_LEVEL_HIGH>;
			#dma-cells = <1>;
			qcom,ee = <0>;

			num-channels = <6>;
			qcom,num-ees = <1>;
			qcom,remote-power-collapse;

			status = "disabled";
		};

		sdhc_1: sdhci@7824900 {
			compatible = "qcom,sdhci-msm-v4";
			reg = <0x07824900 0x500>, <0x07824000 0x800>;
			reg-names = "hc_mem", "core_mem";

			interrupts = <GIC_SPI 123 IRQ_TYPE_LEVEL_HIGH>,
				     <GIC_SPI 138 IRQ_TYPE_LEVEL_HIGH>;
			interrupt-names = "hc_irq", "pwr_irq";
			clocks = <&gcc GCC_SDCC1_APPS_CLK>,
				 <&gcc GCC_SDCC1_AHB_CLK>,
				 <&xo_board>;
			clock-names = "core", "iface", "xo";
			mmc-hs200-1_8v;
			mmc-hs400-1_8v;
			mmc-ddr-1_8v;
			bus-width = <8>;
			non-removable;
			status = "disabled";
		};

		sdhc_2: sdhci@7864900 {
			compatible = "qcom,sdhci-msm-v4";
			reg = <0x07864900 0x500>, <0x07864000 0x800>;
			reg-names = "hc_mem", "core_mem";

			interrupts = <GIC_SPI 125 IRQ_TYPE_LEVEL_HIGH>,
				     <GIC_SPI 221 IRQ_TYPE_LEVEL_HIGH>;
			interrupt-names = "hc_irq", "pwr_irq";
			clocks = <&gcc GCC_SDCC2_APPS_CLK>,
				 <&gcc GCC_SDCC2_AHB_CLK>,
				 <&xo_board>;
			clock-names = "core", "iface", "xo";
			bus-width = <4>;
			status = "disabled";
		};

		blsp1_dma: dma-controller@7884000 {
			compatible = "qcom,bam-v1.7.0";
			reg = <0x07884000 0x1f000>;
			interrupts = <GIC_SPI 238 IRQ_TYPE_LEVEL_HIGH>;
			clocks = <&gcc GCC_BLSP1_AHB_CLK>;
			clock-names = "bam_clk";
			#dma-cells = <1>;
			qcom,ee = <0>;
			status = "disabled";
		};

		blsp1_uart1: serial@78af000 {
			compatible = "qcom,msm-uartdm-v1.4", "qcom,msm-uartdm";
			reg = <0x078af000 0x200>;
			interrupts = <GIC_SPI 107 IRQ_TYPE_LEVEL_HIGH>;
			clocks = <&gcc GCC_BLSP1_UART1_APPS_CLK>,
				<&gcc GCC_BLSP1_AHB_CLK>;
			clock-names = "core", "iface";
			dmas = <&blsp1_dma 1>, <&blsp1_dma 0>;
			dma-names = "rx", "tx";
			pinctrl-names = "default", "sleep";
			pinctrl-0 = <&blsp1_uart1_active>;
			pinctrl-1 = <&blsp1_uart1_sleep>;
			status = "disabled";
		};

		blsp1_uart2: serial@78b0000 {
			compatible = "qcom,msm-uartdm-v1.4", "qcom,msm-uartdm";
			reg = <0x078b0000 0x200>;
			interrupts = <GIC_SPI 108 IRQ_TYPE_LEVEL_HIGH>;
			clocks = <&gcc GCC_BLSP1_UART2_APPS_CLK>,
				<&gcc GCC_BLSP1_AHB_CLK>;
			clock-names = "core", "iface";
			dmas = <&blsp1_dma 3>, <&blsp1_dma 2>;
			dma-names = "rx", "tx";
			pinctrl-names = "default", "sleep";
			pinctrl-0 = <&blsp1_uart1_active>;
			pinctrl-1 = <&blsp1_uart1_sleep>;
			status = "disabled";
		};

		blsp_i2c2: i2c@78b6000 {
			compatible = "qcom,i2c-qup-v2.2.1";
			reg = <0x078b6000 0x600>;
			interrupts = <GIC_SPI 96 IRQ_TYPE_LEVEL_HIGH>;
			clocks = <&gcc GCC_BLSP1_AHB_CLK>,
				<&gcc GCC_BLSP1_QUP2_I2C_APPS_CLK>;
			clock-names = "iface", "core";
			pinctrl-names = "default", "sleep";
			pinctrl-0 = <&i2c_2_default>;
			pinctrl-1 = <&i2c_2_sleep>;
			#address-cells = <1>;
			#size-cells = <0>;
			status = "disabled";
		};

		blsp_i2c3: i2c@78b7000 {
			compatible = "qcom,i2c-qup-v2.2.1";
			reg = <0x078b7000 0x600>;
			interrupts = <GIC_SPI 97 IRQ_TYPE_LEVEL_HIGH>;
			clocks = <&gcc GCC_BLSP1_AHB_CLK>,
				 <&gcc GCC_BLSP1_QUP3_I2C_APPS_CLK>;
			clock-names = "iface", "core";
			pinctrl-names = "default", "sleep";
			pinctrl-0 = <&i2c_3_default>;
			pinctrl-1 = <&i2c_3_sleep>;
			#address-cells = <1>;
			#size-cells = <0>;
			status = "disabled";
		};

		blsp_spi3: spi@78b7000 {
			compatible = "qcom,spi-qup-v2.2.1";
			reg = <0x078b7000 0x600>;
			interrupts = <GIC_SPI 97 IRQ_TYPE_LEVEL_HIGH>;
			clocks = <&gcc GCC_BLSP1_AHB_CLK>,
				<&gcc GCC_BLSP1_QUP3_I2C_APPS_CLK>;
			clock-names = "core", "iface";
			pinctrl-names = "default", "sleep";
			pinctrl-0 = <&spi3_default>;
			pinctrl-1 = <&spi3_sleep>;
			#address-cells = <1>;
			#size-cells = <0>;
			status = "disabled";
		};

		blsp_i2c4: i2c@78b8000 {
			compatible = "qcom,i2c-qup-v2.2.1";
			reg = <0x078b8000 0x500>;
			interrupts = <GIC_SPI 98 IRQ_TYPE_LEVEL_HIGH>;
			clocks = <&gcc GCC_BLSP1_AHB_CLK>,
				<&gcc GCC_BLSP1_QUP4_I2C_APPS_CLK>;
			clock-names = "iface", "core";
			pinctrl-names = "default", "sleep";
			pinctrl-0 = <&i2c_4_default>;
			pinctrl-1 = <&i2c_4_sleep>;
			#address-cells = <1>;
			#size-cells = <0>;
			status = "disabled";
		};

		blsp_i2c5: i2c@7af5000 {
			compatible = "qcom,i2c-qup-v2.2.1";
			reg = <0x07af5000 0x600>;
			interrupts = <GIC_SPI 299 IRQ_TYPE_LEVEL_HIGH>;
			clocks = <&gcc GCC_BLSP2_AHB_CLK>,
				<&gcc GCC_BLSP2_QUP1_I2C_APPS_CLK>;
			clock-names = "iface", "core";
			pinctrl-names = "default", "sleep";
			pinctrl-0 = <&i2c_5_default>;
			pinctrl-1 = <&i2c_5_sleep>;
			#address-cells = <1>;
			#size-cells = <0>;
			status = "disabled";
		};

		blsp_spi6: spi@7af6000 {
			compatible = "qcom,spi-qup-v2.2.1";
			reg = <0x07af6000 0x600>;
			interrupts = <GIC_SPI 300 IRQ_TYPE_LEVEL_HIGH>;
			clocks = <&gcc GCC_BLSP2_AHB_CLK>,
				<&gcc GCC_BLSP2_QUP2_SPI_APPS_CLK>;
			clock-names = "iface", "core";
			pinctrl-names = "default", "sleep";
			pinctrl-0 = <&spi6_default>;
			pinctrl-1 = <&spi6_sleep>;
			#address-cells = <1>;
			#size-cells = <0>;
			status = "disabled";
		};

		pronto: remoteproc@a204000 {
			compatible = "qcom,pronto-v3-pil", "qcom,pronto";
			reg = <0x0a204000 0x2000>, <0x0a202000 0x1000>, <0x0a21b000 0x3000>;
			reg-names = "ccu", "dxe", "pmu";

			memory-region = <&wcnss_fw_mem>;

			interrupts-extended = <&intc GIC_SPI 149 IRQ_TYPE_EDGE_RISING>,
					      <&smp2p_wcnss_in 0 IRQ_TYPE_EDGE_RISING>,
					      <&smp2p_wcnss_in 1 IRQ_TYPE_EDGE_RISING>,
					      <&smp2p_wcnss_in 2 IRQ_TYPE_EDGE_RISING>,
					      <&smp2p_wcnss_in 3 IRQ_TYPE_EDGE_RISING>;
			interrupt-names = "wdog", "fatal", "ready", "handover", "stop-ack";

			power-domains = <&rpmpd MSM8937_VDDCX>, <&rpmpd MSM8937_VDDMX>;
			power-domain-names = "cx", "mx";

			qcom,smem-states = <&smp2p_wcnss_out 0>;
			qcom,smem-state-names = "stop";

			pinctrl-names = "default", "sleep";
			pinctrl-0 = <&wcnss_default>;
			pinctrl-1 = <&wcnss_sleep>;

			status = "okay";

			wcnss_iris: iris {
				/* Separate chip, compatible is board-specific */
				clocks = <&rpmcc RPM_SMD_RF_CLK2>;
				clock-names = "xo";
			};

			smd-edge {
				interrupts = <GIC_SPI 142 IRQ_TYPE_EDGE_RISING>;

				qcom,ipc = <&apcs 8 17>;
				qcom,smd-edge = <6>;
				qcom,remote-pid = <4>;

				label = "pronto";

				wcnss_ctrl: wcnss  {
					compatible = "qcom,wcnss";
					qcom,smd-channels = "WCNSS_CTRL";

					qcom,mmio = <&pronto>;

					wcnss_bt: bluetooth {
						compatible = "qcom,wcnss-bt";
					};

					wcnss_wifi: wifi {
						compatible = "qcom,wcnss-wlan";

						interrupts = <GIC_SPI 145 IRQ_TYPE_LEVEL_HIGH>,
							     <GIC_SPI 146 IRQ_TYPE_LEVEL_HIGH>;
						interrupt-names = "tx", "rx";

						qcom,smem-states = <&apps_smsm 10>, <&apps_smsm 9>;
						qcom,smem-state-names = "tx-enable", "tx-rings-empty";
					};
				};
			};
		};

		intc: interrupt-controller@b000000 {
			compatible = "qcom,msm-qgic2";
			interrupt-controller;
			#interrupt-cells = <3>;
			reg = <0x0b000000 0x1000>,
			      <0x0b002000 0x1000>;
		};

		timer@b120000 {
			#address-cells = <1>;
			#size-cells = <1>;
			ranges;
			compatible = "arm,armv7-timer-mem";
			reg = <0x0b120000 0x1000>;
			clock-frequency = <19200000>;

			frame@b121000 {
				frame-number = <0>;
				interrupts = <GIC_SPI 8 IRQ_TYPE_LEVEL_HIGH>,
					     <GIC_SPI 7 IRQ_TYPE_LEVEL_HIGH>;
				reg = <0x0b121000 0x1000>,
				      <0x0b122000 0x1000>;
			};

			frame@b123000 {
				frame-number = <1>;
				interrupts = <GIC_SPI 9 IRQ_TYPE_LEVEL_HIGH>;
				reg = <0x0b123000 0x1000>;
				status = "disabled";
			};

			frame@b124000 {
				frame-number = <2>;
				interrupts = <GIC_SPI 10 IRQ_TYPE_LEVEL_HIGH>;
				reg = <0x0b124000 0x1000>;
				status = "disabled";
			};

			frame@b125000 {
				frame-number = <3>;
				interrupts = <GIC_SPI 11 IRQ_TYPE_LEVEL_HIGH>;
				reg = <0x0b125000 0x1000>;
				status = "disabled";
			};

			frame@b126000 {
				frame-number = <4>;
				interrupts = <GIC_SPI 12 IRQ_TYPE_LEVEL_HIGH>;
				reg = <0x0b126000 0x1000>;
				status = "disabled";
			};

			frame@b127000 {
				frame-number = <5>;
				interrupts = <GIC_SPI 13 IRQ_TYPE_LEVEL_HIGH>;
				reg = <0xb127000 0x1000>;
				status = "disabled";
			};

			frame@b128000 {
				frame-number = <6>;
				interrupts = <GIC_SPI 14 IRQ_TYPE_LEVEL_HIGH>;
				reg = <0x0b128000 0x1000>;
				status = "disabled";
			};
		};
	};
};
